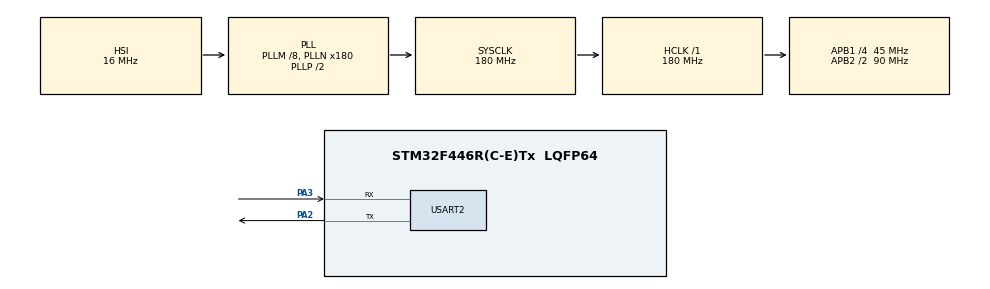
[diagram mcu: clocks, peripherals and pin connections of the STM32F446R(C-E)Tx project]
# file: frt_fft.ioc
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FREERTOS.Tasks01=defaultTask,24,128,StartDefaultTask,Default,NULL,Dynamic,NULL,NULL
FREERTOS.configUSE_NEWLIB_REENTRANT=1
Mcu.Family=STM32F4
Mcu.Name=STM32F446R(C-E)Tx
Mcu.Package=LQFP64
NVIC.PriorityGroup=NVIC_PRIORITYGROUP_4
NVIC.TIM1_UP_TIM10_IRQn=true\:15\:0\:false\:false\:true\:false\:false\:true\:true
NVIC.TimeBase=TIM1_UP_TIM10_IRQn
NVIC.TimeBaseIP=TIM1
PA2.Mode=Asynchronous
PA2.Signal=USART2_TX
PA3.Mode=Asynchronous
PA3.Signal=USART2_RX
ProjectManager.HeapSize=0x200
ProjectManager.StackSize=0x400
ProjectManager.TargetToolchain=STM32CubeIDE
RCC.AHBFreq_Value=180000000
RCC.APB1CLKDivider=RCC_HCLK_DIV4
RCC.APB1Freq_Value=45000000
RCC.APB1TimFreq_Value=90000000
RCC.APB2CLKDivider=RCC_HCLK_DIV2
RCC.APB2Freq_Value=90000000
RCC.APB2TimFreq_Value=180000000
RCC.CortexFreq_Value=180000000
RCC.HCLKFreq_Value=180000000
RCC.PLLM=8
RCC.PLLN=180
RCC.SYSCLKFreq_VALUE=180000000
RCC.SYSCLKSource=RCC_SYSCLKSOURCE_PLLCLK
RCC.USBFreq_Value=180000000
RCC.VCOOutputFreq_Value=360000000
USART2.VirtualMode=VM_ASYNC
VP_FREERTOS_VS_CMSIS_V2.Mode=CMSIS_V2
VP_SYS_VS_tim1.Mode=TIM1
board=custom

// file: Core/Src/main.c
/* USER CODE BEGIN Header */
/**
 ******************************************************************************
 * @file           : main.c
 * @brief          : Main program body
 ******************************************************************************
 * @attention
 *
 * Copyright (c) 2025 STMicroelectronics.
 * All rights reserved.
 *
 * This software is licensed under terms that can be found in the LICENSE file
 * in the root directory of this software component.
 * If no LICENSE file comes with this software, it is provided AS-IS.
 *
 ******************************************************************************
 */
/* USER CODE END Header */
#include "main.h"
#include "cmsis_os.h"

/* USER CODE BEGIN PD */
#define N_FFT          1024      // Dimensione FFT (reale)
#define NUM_ITER       100      // Numero di iterazioni per il benchmark
/* USER CODE END PD */

UART_HandleTypeDef huart2;

/* Definitions for defaultTask */
osThreadId_t defaultTaskHandle;
const osThreadAttr_t defaultTask_attributes = {
		.name = "defaultTask",
		.stack_size = 2048 * 4,
		.priority = (osPriority_t) osPriorityNormal,
};
/* USER CODE BEGIN PV */
// Buffer complesso: [re0, im0, re1, im1, ...]
static float buf[2 * N_FFT];
volatile uint32_t total_cycles = 0;
volatile uint32_t avg_cycles   = 0;
/* USER CODE END PV */

void SystemClock_Config(void);
static void MX_GPIO_Init(void);
static void MX_USART2_UART_Init(void);
void StartDefaultTask(void *argument);

/* USER CODE BEGIN 0 */
static void init_buffer(void) {
	for (int i = 0; i < N_FFT; ++i) {
		float x = (float)i;
		buf[2 * i + 0] = x;        // re
		buf[2 * i + 1] = 0.5f * x; // im
	}
}

static void fft_like_step(void) {
	for (int i = 0; i < N_FFT; i += 2) {
		int ia = i;
		int ib = i + 1;

		float a_re = buf[2 * ia + 0];
		float a_im = buf[2 * ia + 1];
		float b_re = buf[2 * ib + 0];
		float b_im = buf[2 * ib + 1];

		float u_re = a_re + b_re;
		float u_im = a_im + b_im;
		float v_re = a_re - b_re;
		float v_im = a_im - b_im;

		// simulazione twiddle / scaling
		u_re *= 0.5f;
		u_im *= 0.5f;
		v_re *= 0.5f;
		v_im *= 0.5f;

		buf[2 * ia + 0] = u_re;
		buf[2 * ia + 1] = u_im;
		buf[2 * ib + 0] = v_re;
		buf[2 * ib + 1] = v_im;
	}
}

static void bench(int iterations) {
	for (int k = 0; k < iterations; ++k) {
		fft_like_step();
	}
}

int _write(int file, char *ptr, int len)
{
	HAL_UART_Transmit(&huart2, (uint8_t*)ptr, len, HAL_MAX_DELAY);
	return len;
}

//------------------------------
// DWT cycle counter
//------------------------------
static void DWT_Init(void) {
	// abilita il blocco di trace
	CoreDebug->DEMCR |= CoreDebug_DEMCR_TRCENA_Msk;
	// azzera il contatore
	DWT->CYCCNT = 0;
	// abilita il contatore di cicli
	DWT->CTRL |= DWT_CTRL_CYCCNTENA_Msk;
}

void run_benchmark(void) {
	DWT_Init();
	init_buffer();

	uint32_t start = DWT->CYCCNT;
	bench(NUM_ITER);
	uint32_t end   = DWT->CYCCNT;

	total_cycles = end - start;
	avg_cycles   = total_cycles / NUM_ITER;
}
/* USER CODE END 0 */

int main(void)
{

	/* MCU Configuration--------------------------------------------------------*/

	/* Reset of all peripherals, Initializes the Flash interface and the Systick. */
	HAL_Init();

	/* Configure the system clock */
	SystemClock_Config();

	/* Initialize all configured peripherals */
	MX_GPIO_Init();
	MX_USART2_UART_Init();

	/* Init scheduler */
	osKernelInitialize();

	/* Create the thread(s) */
	/* creation of defaultTask */
	defaultTaskHandle = osThreadNew(StartDefaultTask, NULL, &defaultTask_attributes);

	/* Start scheduler */
	osKernelStart();

	/* We should never get here as control is now taken by the scheduler */

	/* Infinite loop */
	while (1)
	{

	}
}

void SystemClock_Config(void)
{
	RCC_OscInitTypeDef RCC_OscInitStruct = {0};
	RCC_ClkInitTypeDef RCC_ClkInitStruct = {0};

	/** Configure the main internal regulator output voltage
	 */
	__HAL_RCC_PWR_CLK_ENABLE();
	__HAL_PWR_VOLTAGESCALING_CONFIG(PWR_REGULATOR_VOLTAGE_SCALE1);

	/** Initializes the RCC Oscillators according to the specified parameters
	 * in the RCC_OscInitTypeDef structure.
	 */
	RCC_OscInitStruct.OscillatorType = RCC_OSCILLATORTYPE_HSI;
	RCC_OscInitStruct.HSIState = RCC_HSI_ON;
	RCC_OscInitStruct.HSICalibrationValue = RCC_HSICALIBRATION_DEFAULT;
	RCC_OscInitStruct.PLL.PLLState = RCC_PLL_ON;
	RCC_OscInitStruct.PLL.PLLSource = RCC_PLLSOURCE_HSI;
	RCC_OscInitStruct.PLL.PLLM = 8;
	RCC_OscInitStruct.PLL.PLLN = 180;
	RCC_OscInitStruct.PLL.PLLP = RCC_PLLP_DIV2;
	RCC_OscInitStruct.PLL.PLLQ = 2;
	RCC_OscInitStruct.PLL.PLLR = 2;
	if (HAL_RCC_OscConfig(&RCC_OscInitStruct) != HAL_OK)
	{
		Error_Handler();
	}

	/** Activate the Over-Drive mode
	 */
	if (HAL_PWREx_EnableOverDrive() != HAL_OK)
	{
		Error_Handler();
	}

	/** Initializes the CPU, AHB and APB buses clocks
	 */
	RCC_ClkInitStruct.ClockType = RCC_CLOCKTYPE_HCLK|RCC_CLOCKTYPE_SYSCLK
			|RCC_CLOCKTYPE_PCLK1|RCC_CLOCKTYPE_PCLK2;
	RCC_ClkInitStruct.SYSCLKSource = RCC_SYSCLKSOURCE_PLLCLK;
	RCC_ClkInitStruct.AHBCLKDivider = RCC_SYSCLK_DIV1;
	RCC_ClkInitStruct.APB1CLKDivider = RCC_HCLK_DIV4;
	RCC_ClkInitStruct.APB2CLKDivider = RCC_HCLK_DIV2;

	if (HAL_RCC_ClockConfig(&RCC_ClkInitStruct, FLASH_LATENCY_5) != HAL_OK)
	{
		Error_Handler();
	}
}

static void MX_USART2_UART_Init(void)
{

	huart2.Instance = USART2;
	huart2.Init.BaudRate = 115200;
	huart2.Init.WordLength = UART_WORDLENGTH_8B;
	huart2.Init.StopBits = UART_STOPBITS_1;
	huart2.Init.Parity = UART_PARITY_NONE;
	huart2.Init.Mode = UART_MODE_TX_RX;
	huart2.Init.HwFlowCtl = UART_HWCONTROL_NONE;
	huart2.Init.OverSampling = UART_OVERSAMPLING_16;
	if (HAL_UART_Init(&huart2) != HAL_OK)
	{
		Error_Handler();
	}

}

static void MX_GPIO_Init(void)
{

	/* GPIO Ports Clock Enable */
	__HAL_RCC_GPIOA_CLK_ENABLE();

}

void StartDefaultTask(void *argument)
{
	/* USER CODE BEGIN 5 */
	SysTick->CTRL = 0;   // disabilita SysTick
	__disable_irq();     // opzionale se vuoi togliere tutte le IRQ
	run_benchmark();

	printf("FreeRTOS\r\n");
	printf("Total cycles: %lu\r\n", (unsigned long)total_cycles);
	printf("Avg cycles per FFT: %lu\r\n", (unsigned long)avg_cycles);
	/* Infinite loop */
	for(;;)
	{
		osDelay(1);
	}
	/* USER CODE END 5 */
}

void HAL_TIM_PeriodElapsedCallback(TIM_HandleTypeDef *htim)
{
	if (htim->Instance == TIM1)
	{
		HAL_IncTick();
	}
}

void Error_Handler(void)
{
	__disable_irq();
	while (1)
	{
	}
}
